AUTOSAR XML (schema 4-3-0)
package /CollisionDetectionBSW/Services/ComM
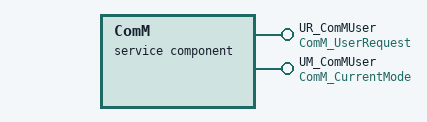
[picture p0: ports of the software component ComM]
  service sw component type ComM
    provide port UR_ComMUser: provided-interface=ComM_UserRequest
    provide port UM_ComMUser: provided-interface=ComM_CurrentMode
    behavior ComMBehavior: data-type-mapping=ComMTypeMappings, handle-termination-and-restart=NO-SUPPORT, port-api-option{port-defined-argument-value{value=ComM_UserHandleType:0, value-type=ComM_UserHandleType}, port=UR_ComMUser}
      4 x operation invoked event:
        RequestComMode_UR_ComMUser_RequestComMode: start-on-event=RequestComMode, operation=UR_ComMUser.RequestComMode
        GetMaxComMode_UR_ComMUser_GetMaxComMode: start-on-event=GetMaxComMode, operation=UR_ComMUser.GetMaxComMode
        GetRequestedComMode_UR_ComMUser_GetRequestedComMode: start-on-event=GetRequestedComMode, operation=UR_ComMUser.GetRequestedComMode
        GetCurrentComMode_UR_ComMUser_GetCurrentComMode: start-on-event=GetCurrentComMode, operation=UR_ComMUser.GetCurrentComMode
      5 x runnable:
        ComM_MainFunction
          mode switch point modeSwitchPoint_ComM_MainFunction_UM_ComMUser_currentMode: mode-group=UM_ComMUser.currentMode
        RequestComMode: can-be-invoked-concurrently=true, symbol=ComM_RequestComMode
        GetMaxComMode: can-be-invoked-concurrently=true, symbol=ComM_GetMaxComMode
        GetRequestedComMode: can-be-invoked-concurrently=true, symbol=ComM_GetRequestedComMode
        GetCurrentComMode: can-be-invoked-concurrently=true, symbol=ComM_GetCurrentComMode
  swc implementation ComMImpl: programming-language=C, vendor-id=60, behavior=ComMBehavior
    code-descriptors:
      code src: artifact-descriptors=autosar-engineering-object={short-label=artifactDescriptor, category=artifactDescriptorCategory}
    resource consumption resourceConsumption
